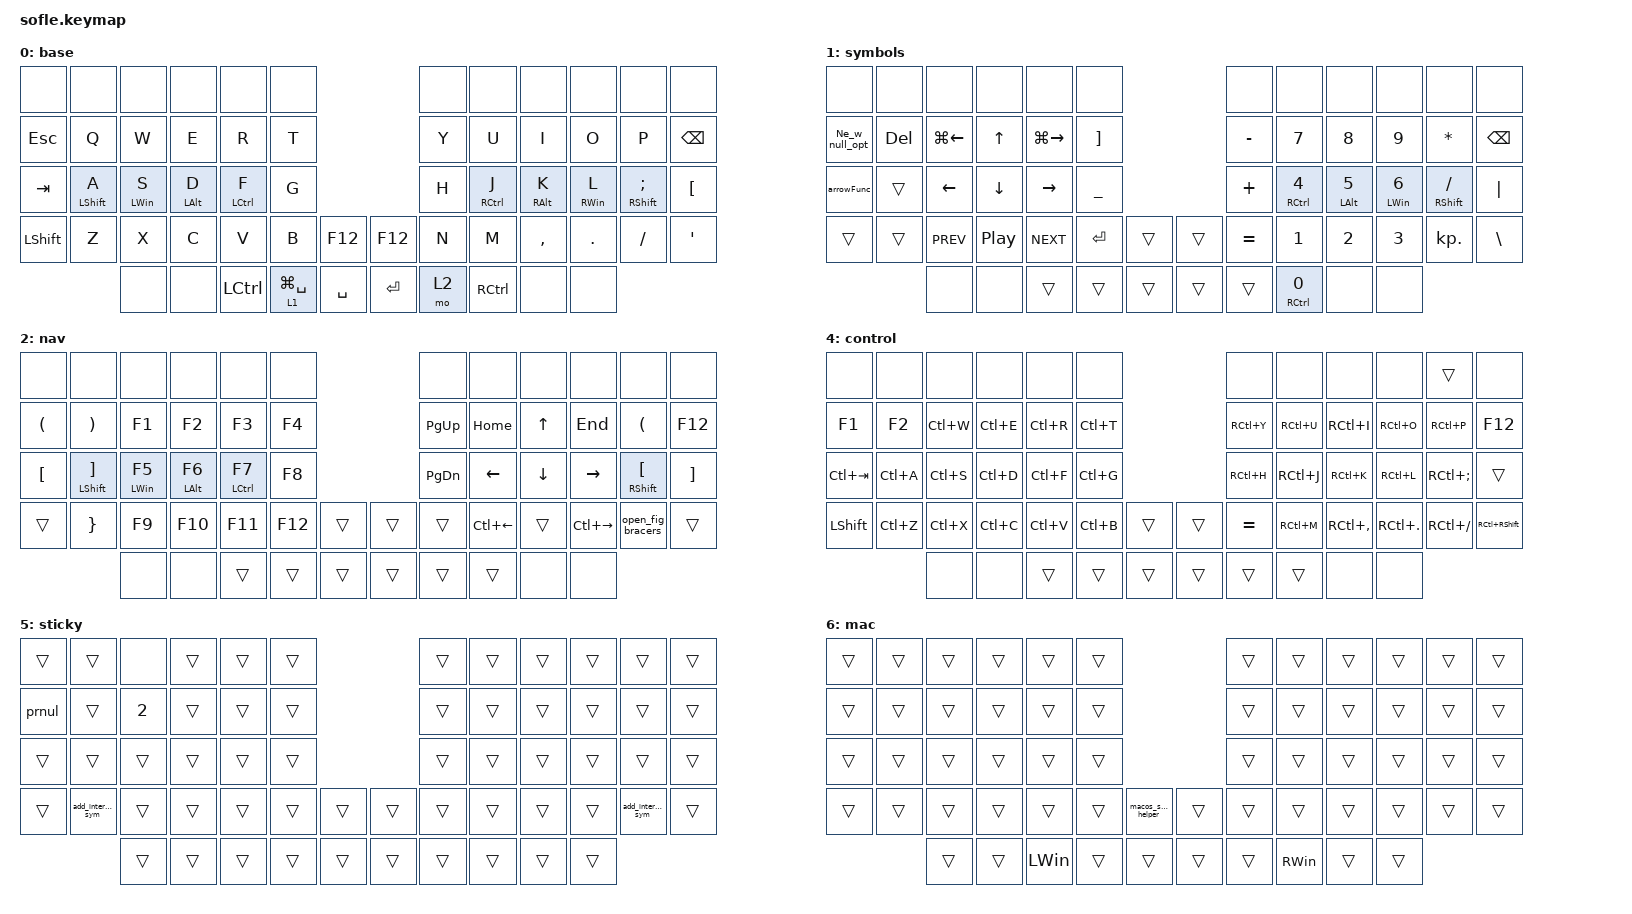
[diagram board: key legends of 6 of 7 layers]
#include <behaviors.dtsi>
#include <dt-bindings/zmk/bt.h>
#include <dt-bindings/zmk/ext_power.h>
#include <dt-bindings/zmk/keys.h>
#include <dt-bindings/zmk/rgb.h>

#define BASE 0
#define SYMBOLS 1
#define NAV 2
#define ADJUST 3
#define CONTROL 4
#define STICKY 5
#define MAC 6

&mt { flavor = "tap-preferred"; };

/ {

    conditional_layers {
        compatible = "zmk,conditional-layers";

        adjust_layer {
            if-layers = <1 2>;
            then-layer = <3>;
        };
    };

    sensors: sensors {
        compatible = "zmk,keymap-sensors";
        sensors = <&left_encoder &right_encoder>;
        triggers-per-rotation = <18>;
    };

    left_encoder: encoder_left { steps = <36>; };

    right_encoder: encoder_right { steps = <36>; };

    behaviors {
        smart_ht: smart_ht {
            compatible = "zmk,behavior-hold-tap";
            #binding-cells = <2>;
            flavor = "tap-preferred";
            tapping-term-ms = <150>;
            bindings = <&tap_arg>, <&kp>;
        };

        layer_tap_macro: layer_tap_macro {
            compatible = "zmk,behavior-hold-tap";
            label = "LAYER_TAP_MACRO";
            bindings = <&mo>, <&kp>;
            #binding-cells = <2>;
            tapping-term-ms = <170>;
        };
    };

    macros {
        nonEquals: nonEquals {
            compatible = "zmk,behavior-macro";
            #binding-cells = <0>;
            bindings = <&kp EXCL &kp EQUAL>;
            label = "EXCL";
        };

        arrowFunc: arrowFunc {
            compatible = "zmk,behavior-macro";
            #binding-cells = <0>;
            bindings = <&kp EQUAL &kp GT>;
            label = "ARROWFUNC";
        };

        macos_switch_helper: macos_switch_helper {
            compatible = "zmk,behavior-macro";
            #binding-cells = <0>;
            bindings =
                <&macro_press>,
                <&tog 5 &kt LGUI>,
                <&macro_pause_for_release>,
                <&tog 5 &kt LGUI>;

            label = "MACOS_SWITCH_HELPER";
        };

        win_switch_helper: win_switch_helper {
            compatible = "zmk,behavior-macro";
            #binding-cells = <0>;
            bindings =
                <&macro_press>,
                <&tog 5 &kt LALT>,
                <&macro_pause_for_release>,
                <&tog 5 &kt LALT>,
                <&macro_press>;

            label = "WIN_SWITCH_HELPER";
        };

        Ne_w_null_opt: Ne_w_null_opt {
            compatible = "zmk,behavior-macro";
            #binding-cells = <0>;
            bindings = <&kp EXCLAMATION &kp EQUAL &sl 5>;
            label = "NE_W_NULL_OPT";
            tap-ms = <0>;
        };

        prnul: null {
            compatible = "zmk,behavior-macro";
            #binding-cells = <0>;
            bindings = <&kp SPACE &kp N &kp U &kp L &kp L &tog 0>;
            label = "NULL";
        };

        open_fig_bracers: open_fig_bracers {
            compatible = "zmk,behavior-macro";
            #binding-cells = <0>;
            bindings = <&kp LBRC &kp RBRC &sl 5>;
            label = "OPEN_FIG_BRACERS";
        };

        add_interpolation_sym: add_interpolation_sym {
            compatible = "zmk,behavior-macro";
            #binding-cells = <0>;
            bindings = <&kp LEFT_ARROW &kp DOLLAR &kp RIGHT_ARROW &tog 0>;
            label = "ADD_INTERPOLATION_SYM";
        };

        tap_arg: tap_arg {
            compatible = "zmk,behavior-macro-one-param";
            #binding-cells = <1>;
            bindings = <&macro_param_1to1 &kp MACRO_PLACEHOLDER>;
        };
    };

    keymap {
        compatible = "zmk,keymap";

        base {
            display-name = "base";


            bindings = <
&none       &none        &none      &none      &none       &none                                                        &none  &none       &none       &none            &none            &none
&kp ESCAPE  &kp Q        &kp W      &kp E      &kp R       &kp T                                                        &kp Y  &kp U       &kp I       &kp O            &kp P            &kp BACKSPACE  
&kp TAB     &mt LSHIFT A &mt LWIN S &mt LALT D &mt LCTRL F &kp G                                                        &kp H  &mt RCTRL J &mt RALT K  &mt RWIN L       &mt RSHFT SEMI   &kp LBKT
&kp LSHFT   &kp Z        &kp X      &kp C      &kp V       &kp B                         &kp F12             &kp F12    &kp N  &kp M       &kp COMMA   &kp DOT          &kp FSLH         &kp SQT
                         &none      &none      &kp LCTRL   &layer_tap_macro 1 LG(SPACE)  &kp SPACE           &kp ENTER  &mo 2  &kp RCTRL   &none       &none
            >;

            sensor-bindings =
                <&inc_dec_kp LC(PAGE_DOWN) LC(PAGE_UP)>,
                <&inc_dec_kp TAB LS(TAB)>;
        };

        symbols {
            display-name = "symbols";


            bindings = <
&none           &none       &none           &none             &none          &none                                &none      &none               &none              &none             &none           &none
&Ne_w_null_opt  &kp DEL     &kp LG(LEFT)    &kp UP_ARROW      &kp LG(RIGHT)  &kp RIGHT_BRACKET                    &kp MINUS  &kp NUMBER_7        &kp NUMBER_8       &kp NUMBER_9      &kp ASTRK       &kp BACKSPACE
&arrowFunc      &trans      &kp LEFT_ARROW  &kp DOWN_ARROW    &kp RIGHT      &kp UNDER                            &kp PLUS   &mt RCTRL NUMBER_4  &mt LALT NUMBER_5  &mt LWIN NUMBER_6 &mt RSHFT FSLH  &kp PIPE
&trans          &trans      &kp C_PREV      &kp C_PLAY_PAUSE  &kp C_NEXT     &kp ENTER          &trans    &trans  &kp EQUAL  &kp NUMBER_1        &kp NUMBER_2       &kp NUMBER_3      &kp KP_DOT      &kp BSLH
                            &none           &none             &trans         &trans             &trans    &trans  &trans     &mt RCTRL NUMBER_0  &none              &none
            >;

            sensor-bindings =
                <&inc_dec_kp LC(PAGE_DOWN) LC(PAGE_UP)>,
                <&inc_dec_kp LC(C_VOLUME_UP) LC(C_VOLUME_DOWN)>;
        };

        nav {
            display-name = "nav";


            bindings = <
&none     &none             &none        &none         &none         &none                             &none      &none           &none          &none           &none              &none 
&kp LPAR  &kp RPAR          &kp F1       &kp F2        &kp F3        &kp F4                            &kp PG_UP  &kp HOME        &kp UP         &kp END         &kp LPAR           &kp F12
&kp LBKT  &mt LSHIFT RBKT   &mt LWIN F5  &mt LALT F6   &mt LCTRL F7  &kp F8                            &kp PG_DN  &kp LEFT        &kp DOWN       &kp RIGHT       &mt RSHFT LBKT     &kp RBKT
&trans    &kp RBRC          &kp F9       &kp F10       &kp F11       &kp F12       &trans    &trans    &trans     &kp LC(LEFT)    &trans         &kp LC(RIGHT)   &open_fig_bracers  &trans
                            &none        &none         &trans        &trans        &trans    &trans    &trans     &trans          &none          &none
            >;

            sensor-bindings = <&inc_dec_kp C_VOL_UP C_VOL_DN &inc_dec_kp PG_UP PG_DN>;
        };

        adjust {

            display-name = "adjust";
            bindings = <
&none              &none            &none            &none            &none                                             &none   &none   &none           &none   &none  &none
&bt BT_CLR         &bt BT_SEL 0     &bt BT_SEL 1     &bt BT_SEL 2     &bt BT_SEL 3     &bt BT_SEL 4                     &trans  &trans  &trans          &trans  &trans &none
&trans             &trans           &trans           &trans           &trans           &trans                           &trans  &trans  &studio_unlock  &tog 5  &trans &none
&trans             &trans           &trans           &trans           &trans           &trans           &trans  &trans  &trans  &trans  &trans          &trans  &trans &none
                                    &none            &none            &none            &none            &none   &none   &none   &none   &none           &none
            >;
        };

        control {
            display-name = "control";


            bindings = <
&none        &none      &none      &none      &none      &none                                     &none     &none      &none         &none        &trans        &none
&kp F1       &kp F2     &kp LC(W)  &kp LC(E)  &kp LC(R)  &kp LC(T)                                 &kp RC(Y) &kp RC(U)  &kp RC(I)     &kp RC(O)    &kp RC(P)     &kp F12
&kp LC(TAB)  &kp LC(A)  &kp LC(S)  &kp LC(D)  &kp LC(F)  &kp LC(G)                                 &kp RC(H) &kp RC(J)  &kp RC(K)     &kp RC(L)    &kp RC(SEMI)  &trans
&kp LSHFT    &kp LC(Z)  &kp LC(X)  &kp LC(C)  &kp LC(V)  &kp LC(B)     &trans             &trans   &kp EQUAL &kp RC(M)  &kp RC(COMMA) &kp RC(DOT)  &kp RC(FSLH)  &kp RC(RSHFT)
                        &none      &none      &trans     &trans        &trans             &trans   &trans    &trans     &none         &none
            >;

            sensor-bindings =
                <&inc_dec_kp LC(PAGE_DOWN) LC(PAGE_UP)>,
                <&inc_dec_kp LC(C_VOLUME_UP) LC(C_VOLUME_DOWN)>;
        };


        sticky {
            display-name = "sticky";
            bindings = <
&trans  &trans                  &none         &trans  &trans  &trans                    &trans  &trans  &trans  &trans  &trans                  &trans
&prnul  &trans                  &kp NUMBER_2  &trans  &trans  &trans                    &trans  &trans  &trans  &trans  &trans                  &trans
&trans  &trans                  &trans        &trans  &trans  &trans                    &trans  &trans  &trans  &trans  &trans                  &trans
&trans  &add_interpolation_sym  &trans        &trans  &trans  &trans  &trans    &trans  &trans  &trans  &trans  &trans  &add_interpolation_sym  &trans
                                &trans        &trans  &trans  &trans  &trans    &trans  &trans  &trans  &trans  &trans
            >;

            sensor-bindings =
                <&inc_dec_kp TAB LS(TAB)>,
                <&inc_dec_kp C_VOLUME_UP LS(C_VOL_DN)>;
        };

        mac {
            display-name = "mac";
            bindings = <
&trans  &trans  &trans     &trans    &trans    &trans                                  &trans  &trans    &trans    &trans     &trans  &trans
&trans  &trans  &trans     &trans    &trans    &trans                                  &trans  &trans    &trans    &trans     &trans  &trans
&trans  &trans  &trans     &trans    &trans    &trans                                  &trans  &trans    &trans    &trans     &trans  &trans
&trans  &trans  &trans     &trans    &trans    &trans  &macos_switch_helper    &trans  &trans  &trans    &trans    &trans     &trans  &trans
                &trans     &trans    &kp LWIN  &trans  &trans                  &trans  &trans  &kp RWIN  &trans    &trans   
            >;
        };
    };
};
